# KM1M7CF14 register map
Vendor: Nuvoton Technology Corporation Japan; Series: KM1M7CF; File version: 1.0.3
CPU: CM7 r1p2, little endian, MPU, FPU, double-precision FPU, I-cache, D-cache, ITCM, DTCM, 4 interrupt priority bits
Registers are 32-bit, read-write, no defined reset value unless marked. A register's access mark holds for its fields unless they carry their own. Offsets are from the block's base; [hi:lo] are bit positions; {n}, {i} and the like mark numbered series.

## PORT — I/O Port
Base 0x4005A000
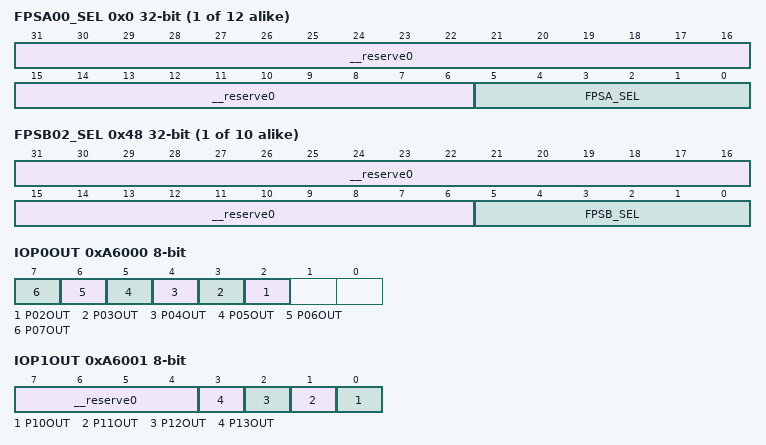
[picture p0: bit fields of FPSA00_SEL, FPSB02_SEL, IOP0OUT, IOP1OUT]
{0x0+4i} FPSA{i:02}_SEL access per field (i=0..11) — FPSA{i:02} Function Selection Register
  [31:6] __reserve0 ro — "0" is always read out.
  [5:0] FPSA_SEL rw — FPSAn function selection
{0x40+4i} FPSB{i:02}_SEL access per field (i=2..11) — FPSB{i:02} Function Selection Register
  [31:6] __reserve0 ro — "0" is always read out.
  [5:0] FPSB_SEL rw — FPSBn function selection
0xA6000 IOP0OUT 8-bit — Port 0 Output Register
  [n] P{n:02}OUT (n=2..7) — Set output data of P{n:02}
0xA6001 IOP1OUT 8-bit access per field — Port 1 Output Register
  [7:4] __reserve0 ro — "0" is always read out.
  [n-10] P{n}OUT rw (n=10..13) — Set output data of P{n}
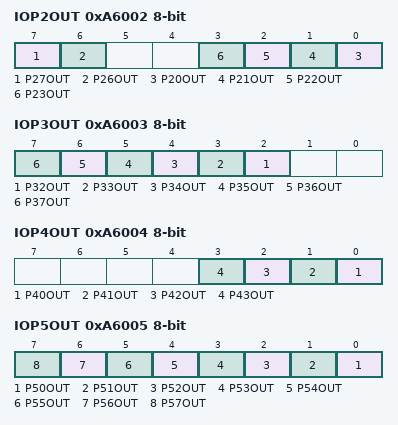
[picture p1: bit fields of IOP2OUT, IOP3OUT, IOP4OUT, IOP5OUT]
0xA6002 IOP2OUT 8-bit — Port 2 Output Register
  [7] P27OUT — Set output data of P27
  [6] P26OUT — Set output data of P26
  [n-20] P{n}OUT (n=20..23) — Set output data of P{n}
0xA6003 IOP3OUT 8-bit — Port 3 Output Register
  [n-30] P{n}OUT (n=32..37) — Set output data of P{n}
0xA6004 IOP4OUT 8-bit — Port 4 Output Register
  [n-40] P{n}OUT (n=40..43) — Set output data of P{n}
0xA6005 IOP5OUT 8-bit — Port 5 Output Register
  [n-50] P{n}OUT (n=50..57) — Set output data of P{n}
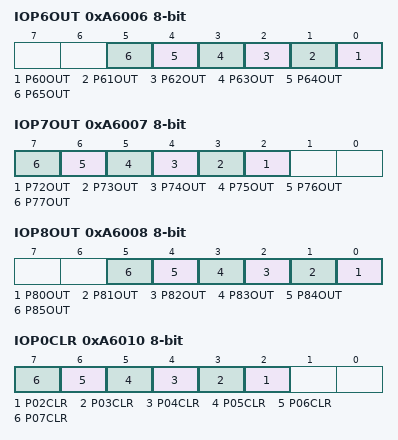
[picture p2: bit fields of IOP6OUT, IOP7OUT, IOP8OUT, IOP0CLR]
0xA6006 IOP6OUT 8-bit — Port 6 Output Register
  [n-60] P{n}OUT (n=60..65) — Set output data of P{n}
0xA6007 IOP7OUT 8-bit — Port 7 Output Register
  [n-70] P{n}OUT (n=72..77) — Set output data of P{n}
0xA6008 IOP8OUT 8-bit — Port 8 Output Register
  [n-80] P{n}OUT (n=80..85) — Set output data of P{n}
0xA6010 IOP0CLR 8-bit wo — Port 0 Output Clear Register
  [n] P{n:02}CLR (n=2..7) — Clear P{n:02}OUT
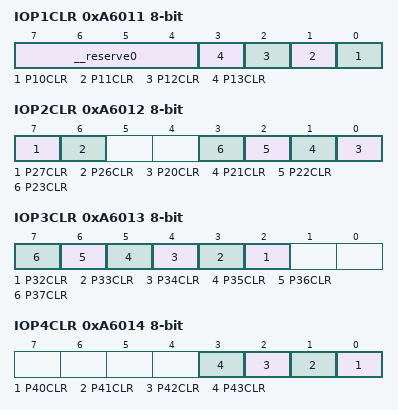
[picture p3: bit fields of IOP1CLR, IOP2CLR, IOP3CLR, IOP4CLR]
0xA6011 IOP1CLR 8-bit access per field — Port 1 Output Clear Register
  [7:4] __reserve0 ro — "0" is always read out.
  [n-10] P{n}CLR wo (n=10..13) — Clear P{n}OUT
0xA6012 IOP2CLR 8-bit wo — Port 2 Output Clear Register
  [7] P27CLR — Clear P27OUT
  [6] P26CLR — Clear P26OUT
  [n-20] P{n}CLR (n=20..23) — Clear P{n}OUT
0xA6013 IOP3CLR 8-bit wo — Port 3 Output Clear Register
  [n-30] P{n}CLR (n=32..37) — Clear P{n}OUT
0xA6014 IOP4CLR 8-bit wo — Port 4 Output Clear Register
  [n-40] P{n}CLR (n=40..43) — Clear P{n}OUT
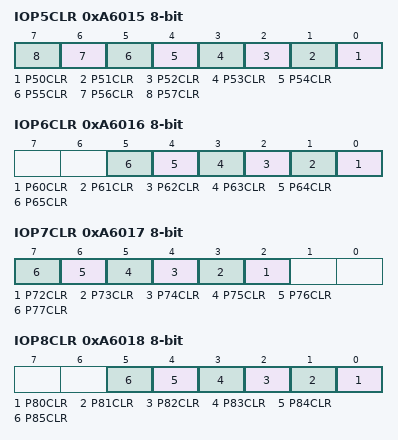
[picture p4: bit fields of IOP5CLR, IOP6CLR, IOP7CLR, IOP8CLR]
0xA6015 IOP5CLR 8-bit wo — Port 5 Output Clear Register
  [n-50] P{n}CLR (n=50..57) — Clear P{n}OUT
0xA6016 IOP6CLR 8-bit wo — Port 6 Output Clear Register
  [n-60] P{n}CLR (n=60..65) — Clear P{n}OUT
0xA6017 IOP7CLR 8-bit wo — Port 7 Output Clear Register
  [n-70] P{n}CLR (n=72..77) — Clear P{n}OUT
0xA6018 IOP8CLR 8-bit wo — Port 8 Output Clear Register
  [n-80] P{n}CLR (n=80..85) — Clear P{n}OUT
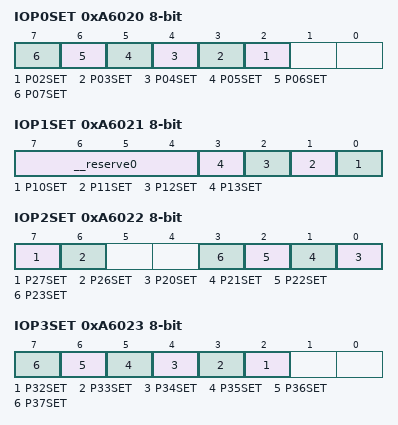
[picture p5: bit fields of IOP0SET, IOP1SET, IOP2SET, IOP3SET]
0xA6020 IOP0SET 8-bit wo — Port 0 Output Set Register
  [n] P{n:02}SET (n=2..7) — Set P{n:02}OUT
0xA6021 IOP1SET 8-bit access per field — Port 1 Output Set Register
  [7:4] __reserve0 ro — "0" is always read out.
  [n-10] P{n}SET wo (n=10..13) — Set P{n}OUT
0xA6022 IOP2SET 8-bit wo — Port 2 Output Set Register
  [7] P27SET — Set P27OUT
  [6] P26SET — Set P26OUT
  [n-20] P{n}SET (n=20..23) — Set P{n}OUT
0xA6023 IOP3SET 8-bit wo — Port 3 Output Set Register
  [n-30] P{n}SET (n=32..37) — Set P{n}OUT
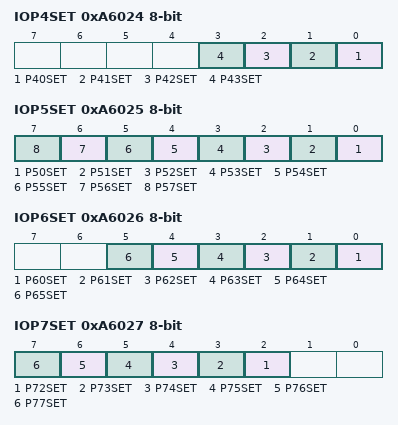
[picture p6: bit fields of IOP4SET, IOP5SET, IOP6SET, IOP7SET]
0xA6024 IOP4SET 8-bit wo — Port 4 Output Set Register
  [n-40] P{n}SET (n=40..43) — Set P{n}OUT
0xA6025 IOP5SET 8-bit wo — Port 5 Output Set Register
  [n-50] P{n}SET (n=50..57) — Set P{n}OUT
0xA6026 IOP6SET 8-bit wo — Port 6 Output Set Register
  [n-60] P{n}SET (n=60..65) — Set P{n}OUT
0xA6027 IOP7SET 8-bit wo — Port 7 Output Set Register
  [n-70] P{n}SET (n=72..77) — Set P{n}OUT
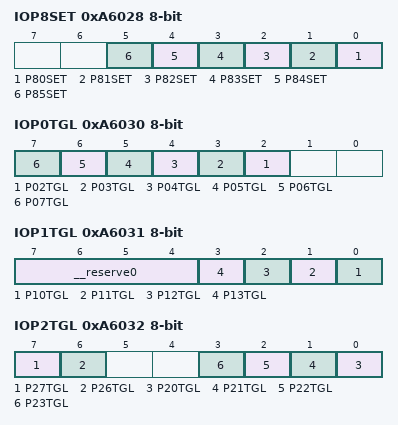
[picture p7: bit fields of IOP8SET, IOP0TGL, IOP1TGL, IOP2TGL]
0xA6028 IOP8SET 8-bit wo — Port 8 Output Set Register
  [n-80] P{n}SET (n=80..85) — Set P{n}OUT
0xA6030 IOP0TGL 8-bit wo — Port 0 Output Toggle Register
  [n] P{n:02}TGL (n=2..7) — Invert P{n:02}OUT
0xA6031 IOP1TGL 8-bit access per field — Port 1 Output Toggle Register
  [7:4] __reserve0 ro — "0" is always read out.
  [n-10] P{n}TGL wo (n=10..13) — Invert P{n}OUT
0xA6032 IOP2TGL 8-bit wo — Port 2 Output Toggle Register
  [7] P27TGL — Invert P27OUT
  [6] P26TGL — Invert P26OUT
  [n-20] P{n}TGL (n=20..23) — Invert P{n}OUT
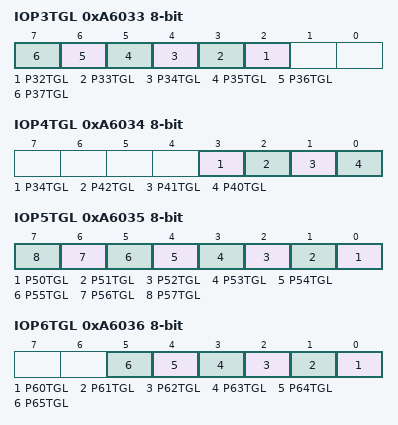
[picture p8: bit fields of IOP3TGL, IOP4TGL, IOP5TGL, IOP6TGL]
0xA6033 IOP3TGL 8-bit wo — Port 3 Output Toggle Register
  [n-30] P{n}TGL (n=32..37) — Invert P{n}OUT
0xA6034 IOP4TGL 8-bit wo — Port 4 Output Toggle Register
  [3] P34TGL — Invert P43OUT
  [2] P42TGL — Invert P42OUT
  [1] P41TGL — Invert P41OUT
  [0] P40TGL — Invert P40OUT
0xA6035 IOP5TGL 8-bit wo — Port 5 Output Toggle Register
  [n-50] P{n}TGL (n=50..57) — Invert P{n}OUT
0xA6036 IOP6TGL 8-bit wo — Port 6 Output Toggle Register
  [n-60] P{n}TGL (n=60..65) — Invert P{n}OUT
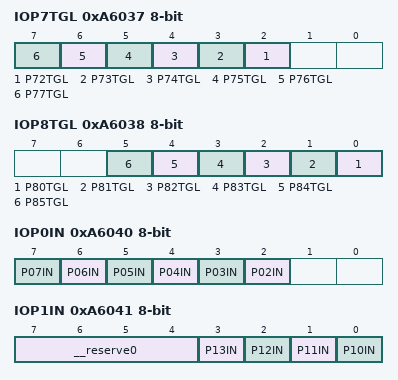
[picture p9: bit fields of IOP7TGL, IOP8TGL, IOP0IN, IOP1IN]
0xA6037 IOP7TGL 8-bit wo — Port 7 Output Toggle Register
  [n-70] P{n}TGL (n=72..77) — Invert P{n}OUT
0xA6038 IOP8TGL 8-bit wo — Port 8 Output Toggle Register
  [n-80] P{n}TGL (n=80..85) — Invert P{n}OUT
0xA6040 IOP0IN 8-bit ro — Port 0 Input Register
  [n] P{n:02}IN (n=2..7) — Input data of P{n:02} is read out.
0xA6041 IOP1IN 8-bit ro — Port 1 Input Register
  [7:4] __reserve0 — "0" is always read out.
  [n-10] P{n}IN (n=10..13) — Input data of P{n} is read out.
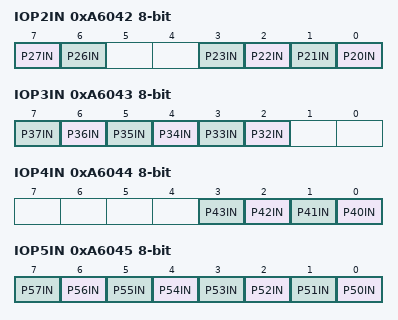
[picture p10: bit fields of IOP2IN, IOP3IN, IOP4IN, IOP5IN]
0xA6042 IOP2IN 8-bit ro — Port 2 Input Register
  [7] P27IN — Input data of P27 is read out.
  [6] P26IN — Input data of P26 is read out.
  [n-20] P{n}IN (n=20..23) — Input data of P{n} is read out.
0xA6043 IOP3IN 8-bit ro — Port 3 Input Register
  [n-30] P{n}IN (n=32..37) — Input data of P{n} is read out.
0xA6044 IOP4IN 8-bit ro — Port 4 Input Register
  [n-40] P{n}IN (n=40..43) — Input data of P{n} is read out.
0xA6045 IOP5IN 8-bit ro — Port 5 Input Register
  [n-50] P{n}IN (n=50..57) — Input data of P{n} is read out.
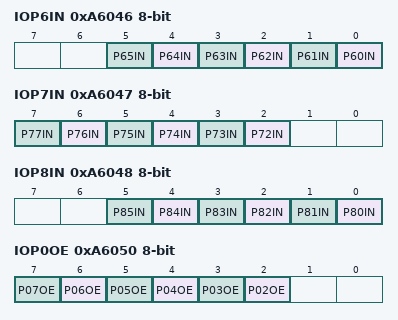
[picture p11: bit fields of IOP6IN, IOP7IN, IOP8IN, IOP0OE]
0xA6046 IOP6IN 8-bit ro — Port 6 Input Register
  [n-60] P{n}IN (n=60..65) — Input data of P{n} is read out.
0xA6047 IOP7IN 8-bit ro — Port 7 Input Register
  [n-70] P{n}IN (n=72..77) — Input data of P{n} is read out.
0xA6048 IOP8IN 8-bit ro — Port 8 Input Register
  [n-80] P{n}IN (n=80..85) — Input data of P{n} is read out.
0xA6050 IOP0OE 8-bit — Port 0 Output Enable Register
  [n] P{n:02}OE (n=2..7) — P{n:02} output enable
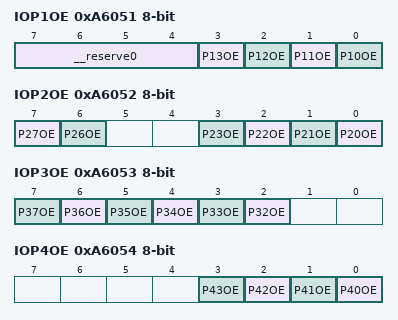
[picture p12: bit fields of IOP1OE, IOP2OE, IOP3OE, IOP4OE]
0xA6051 IOP1OE 8-bit access per field — Port 1 Output Enable Register
  [7:4] __reserve0 ro — "0" is always read out.
  [n-10] P{n}OE rw (n=10..13) — P{n} output enable
0xA6052 IOP2OE 8-bit — Port 2 Output Enable Register
  [7] P27OE — P27 output enable
  [6] P26OE — P26 output enable
  [n-20] P{n}OE (n=20..23) — P{n} output enable
0xA6053 IOP3OE 8-bit — Port 3 Output Enable Register
  [n-30] P{n}OE (n=32..37) — P{n} output enable
0xA6054 IOP4OE 8-bit — Port 4 Output Enable Register
  [n-40] P{n}OE (n=40..43) — P{n} output enable
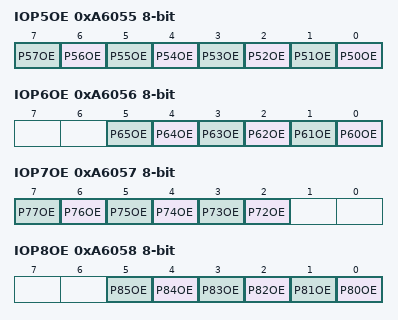
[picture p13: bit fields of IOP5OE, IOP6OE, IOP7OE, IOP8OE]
0xA6055 IOP5OE 8-bit — Port 5 Output Enable Register
  [n-50] P{n}OE (n=50..57) — P{n} output enable
0xA6056 IOP6OE 8-bit — Port 6 Output Enable Register
  [n-60] P{n}OE (n=60..65) — P{n} output enable
0xA6057 IOP7OE 8-bit — Port 7 Output Enable Register
  [n-70] P{n}OE (n=72..77) — P{n} output enable
0xA6058 IOP8OE 8-bit — Port 8 Output Enable Register
  [n-80] P{n}OE (n=80..85) — P{n} output enable
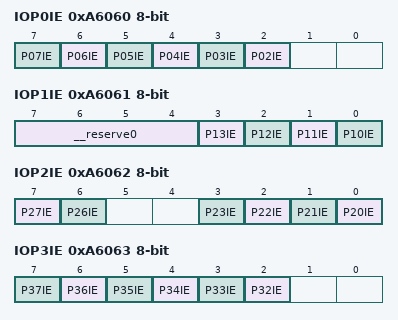
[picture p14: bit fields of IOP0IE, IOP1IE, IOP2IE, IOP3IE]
0xA6060 IOP0IE 8-bit — Port 0 Input Enable Register
  [n] P{n:02}IE (n=2..7) — P{n:02} input enable
0xA6061 IOP1IE 8-bit access per field — Port 1 Input Enable Register
  [7:4] __reserve0 ro — "0" is always read out.
  [n-10] P{n}IE rw (n=10..13) — P{n} input enable
0xA6062 IOP2IE 8-bit — Port 2 Input Enable Register
  [7] P27IE — P27 input enable
  [6] P26IE — P26 input enable
  [n-20] P{n}IE (n=20..23) — P{n} input enable
0xA6063 IOP3IE 8-bit — Port 3 Input Enable Register
  [n-30] P{n}IE (n=32..37) — P{n} input enable
0xA6064 IOP4IE 8-bit — Port 4 Input Enable Register
  [n-40] P{n}IE (n=40..43) — P{n} input enable
0xA6065 IOP5IE 8-bit — Port 5 Input Enable Register
  [n-50] P{n}IE (n=50..57) — P{n} input enable
0xA6066 IOP6IE 8-bit — Port 6 Input Enable Register
  [n-60] P{n}IE (n=60..65) — P{n} input enable
0xA6067 IOP7IE 8-bit — Port 7 Input Enable Register
  [n-70] P{n}IE (n=72..77) — P{n} input enable
0xA6068 IOP8IE 8-bit — Port 8 Input Enable Register
  [n-80] P{n}IE (n=80..85) — P{n} input enable
0xA6071 IOP1ODC 8-bit access per field — Port 1 Nch Open-drain Control Register
  [7:4] __reserve0 ro — "0" is always read out.
  [n-10] P{n}ODC rw (n=10..13) — P{n} Nch open-drain selection
0xA6075 IOP5ODC 8-bit access per field — Port 5 Nch Open-drain Control Register
  [n-50] P{n}ODC rw (n=52..57) — P{n} Nch open-drain selection
  [1:0] __reserve0 ro — "0" is always read out.
0xA6076 IOP6ODC 8-bit — Port 6 Nch Open-drain Control Register
  [n-60] P{n}ODC (n=60..65) — P{n} Nch open-drain selection
0xA6077 IOP7ODC 8-bit — Port 7 Nch Open-drain Control Register
  [n-70] P{n}ODC (n=72..77) — P{n} Nch open-drain selection
0xA6080 IOP0MD — Port 0 Mode Register
  [4n+3:4n] P{n:02}MD (n=2..7) — P{n:02} function selection
0xA6084 IOP1MD access per field — Port 1 Mode Register
  [31:16] __reserve0 ro — "0" is always read out.
  [4n-37:4n-40] P{n}MD rw (n=10..13) — P{n} function selection
0xA6088 IOP2MD — Port 2 Mode Register
  [31:28] P27MD — P27 function selection
  [27:24] P26MD — P26 function selection
  [4n-77:4n-80] P{n}MD (n=20..23) — P{n} function selection
0xA608C IOP3MD — Port 3 Mode Register
  [4n-117:4n-120] P{n}MD (n=32..37) — P{n} function selection
0xA6090 IOP4MD — Port 4 Mode Register
  [4n-157:4n-160] P{n}MD (n=40..43) — P{n} function selection
0xA6094 IOP5MD — Port 5 Mode Register
  [4n-197:4n-200] P{n}MD (n=50..57) — P{n} function selection
0xA6098 IOP6MD — Port 6 Mode Register
  [4n-237:4n-240] P{n}MD (n=60..65) — P{n} function selection
0xA609C IOP7MD — Port 7 Mode Register
  [4n-277:4n-280] P{n}MD (n=72..77) — P{n} function selection
0xA60A0 IOP8MD — Port 8 Mode Register
  [4n-317:4n-320] P{n}MD (n=80..85) — P{n} function selection
0xA60C0 IOP0PLU 8-bit — Port 0 Pull-up Control Register
  [n] P{n:02}PLU (n=2..7) — P{n:02} pull-up resistor selection
0xA60C1 IOP1PLU 8-bit access per field — Port 1 Pull-up Control Register
  [7:4] __reserve0 ro — "0" is always read out.
  [n-10] P{n}PLU rw (n=10..13) — P{n} pull-up resistor selection
0xA60C2 IOP2PLU 8-bit — Port 2 Pull-up Control Register
  [7] P27PLU — P27 pull-up resistor selection
  [6] P26PLU — P26 pull-up resistor selection
  [n-20] P{n}PLU (n=20..23) — P{n} pull-up resistor selection
0xA60C3 IOP3PLU 8-bit — Port 3 Pull-up Control Register
  [n-30] P{n}PLU (n=32..37) — P{n} pull-up resistor selection
0xA60C4 IOP4PLU 8-bit — Port 4 Pull-up Control Register
  [n-40] P{n}PLU (n=40..43) — P{n} pull-up resistor selection
0xA60C5 IOP5PLU 8-bit — Port 5 Pull-up Control Register
  [n-50] P{n}PLU (n=50..57) — P{n} pull-up resistor selection
0xA60C6 IOP6PLU 8-bit — Port 6 Pull-up Control Register
  [n-60] P{n}PLU (n=60..65) — P{n} pull-up resistor selection
0xA60C7 IOP7PLU 8-bit — Port 7 Pull-up Control Register
  [n-70] P{n}PLU (n=72..77) — P{n} pull-up resistor selection
0xA60C8 IOP8PLU 8-bit — Port 8 Pull-up Control Register
  [n-80] P{n}PLU (n=80..85) — P{n} pull-up resistor selection
0xA60D0 IOP0DRV 8-bit — Port 0 Output Current Capacity Control Register
  [n] P{n:02}DRV (n=2..7) — P{n:02} output current capacity selection
0xA60D1 IOP1DRV 8-bit access per field — Port 1 Output Current Capacity Control Register
  [7:4] __reserve0 ro — "0" is always read out.
  [n-10] P{n}DRV rw (n=10..13) — P{n} output current capacity selection
0xA60D2 IOP2DRV 8-bit — Port 2 Output Current Capacity Control Register
  [7] P27DRV — P27 output current capacity selection
  [6] P26DRV — P26 output current capacity selection
  [n-20] P{n}DRV (n=20..23) — P{n} output current capacity selection
0xA60D3 IOP3DRV 8-bit — Port 3 Output Current Capacity Control Register
  [n-30] P{n}DRV (n=32..37) — P{n} output current capacity selection
0xA60D4 IOP4DRV 8-bit — Port 4 Output Current Capacity Control Register
  [n-40] P{n}DRV (n=40..43) — P{n} output current capacity selection
0xA60D5 IOP5DRV 8-bit — Port 5 Output Current Capacity Control Register
  [n-50] P{n}DRV (n=50..57) — P{n} output current capacity selection
0xA60D6 IOP6DRV 8-bit — Port 6 Output Current Capacity Control Register
  [n-60] P{n}DRV (n=60..65) — P{n} output current capacity selection
0xA60D7 IOP7DRV 8-bit — Port 7 Output Current Capacity Control Register
  [n-70] P{n}DRV (n=72..77) — P{n} output current capacity selection
0xA60D8 IOP8DRV 8-bit — Port 8 Output Current Capacity Control Register
  [n-80] P{n}DRV (n=80..85) — P{n} output current capacity selection
0xA60E5 IOP5ILV 8-bit access per field — Port 5 Input Level Selection Register
  [7] P57ILV rw — P57 Input level selection
  [6:0] __reserve0 ro — "0" is always read out.
0xA60E6 IOP6ILV 8-bit access per field — Port 6 Input Level Selection Register
  [7:1] __reserve0 ro — "0" is always read out.
  [0] P60ILV rw — P60 input level selection
